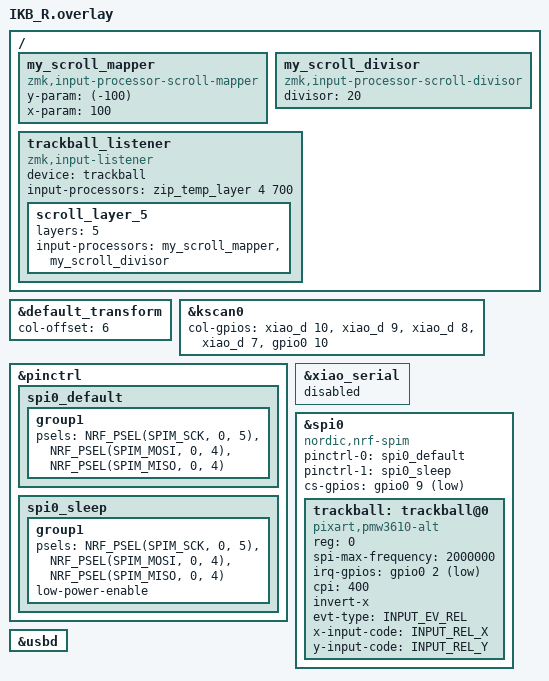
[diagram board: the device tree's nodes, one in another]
/* =========================================================
 * Date: 2026-04-12
 * Filename: config/boards/shields/Test/IKB_R.overlay
 * @details
 * スクロールの上下反転と、スクロール感度（細かさ）の調整を行いました。
 * ZMKの scroll_mapper の仕様に基づき、Y軸の入力乗数を負の値にして
 * 上下を反転させ、変換の分母（divisor）を調整してスクロールを細かくしています。
 * ========================================================= */

#include "IKB.dtsi"
#include <zephyr/dt-bindings/input/input-event-codes.h>
#include <dt-bindings/zmk/pointing.h>
#include <input/processors.dtsi>

&default_transform {
    col-offset = <6>;
};

&kscan0 {
    col-gpios
        = <&xiao_d 10 GPIO_ACTIVE_HIGH>
        , <&xiao_d 9 GPIO_ACTIVE_HIGH> 
        , <&xiao_d 8 GPIO_ACTIVE_HIGH> 
        , <&xiao_d 7 GPIO_ACTIVE_HIGH> 
        , <&gpio0 10 GPIO_ACTIVE_HIGH>
        ;
};

/ {
    /* ---------------------------------------------------
     * 【修正】スクロール変換のカスタム設定
     * 標準の zip_xy_to_scroll_mapper の挙動を上書きし、
     * Y軸の反転と感度（細かさ）の調整を行います。
     * --------------------------------------------------- */
    my_scroll_mapper: my_scroll_mapper {
        compatible = "zmk,input-processor-scroll-mapper";
        /* Y軸の移動量をスクロールに変換。値を変えずに方向だけ反転させるために -100 (マイナス100%) を指定 */
        y-param = <(-100)>;
        /* X軸（横スクロール）はそのまま 100% で変換 */
        x-param = <100>;
    };

    /* カスタム設定したマッパーを通すための追加設定（動きを細かくする分母）*/
    my_scroll_divisor: my_scroll_divisor {
        compatible = "zmk,input-processor-scroll-divisor";
        /* 【ここでスクロールの細かさを調整します】
         * 数字を大きくするとスクロールが細かく(遅く)なり、
         * 数字を小さくするとスクロールが粗く(速く)なります。
         * デフォルトは 10 程度です。今回は少し細かくするため 20 に設定しています。
         * もっと細かくしたい場合は 30 や 40 にしてみてください。
         */
        divisor = <20>;
    };

    trackball_listener {
        compatible = "zmk,input-listener";
        device = <&trackball>; 

        input-processors = <&zip_temp_layer 4 700>;

        scroll_layer_5 {
            layers = <5>;
            /* 上記で作成した「反転マッパー」と「細かくするデバイザ」を適用します */
            input-processors = <&my_scroll_mapper>, <&my_scroll_divisor>;
        };
    };
};

&pinctrl {
    spi0_default: spi0_default {
        group1 {
            psels = <NRF_PSEL(SPIM_SCK, 0, 5)>,
                <NRF_PSEL(SPIM_MOSI, 0, 4)>,
                <NRF_PSEL(SPIM_MISO, 0, 4)>;
        };
    };

    spi0_sleep: spi0_sleep {
        group1 {
            psels = <NRF_PSEL(SPIM_SCK, 0, 5)>,
                <NRF_PSEL(SPIM_MOSI, 0, 4)>,
                <NRF_PSEL(SPIM_MISO, 0, 4)>;
            low-power-enable;
        };                              
    };
};

&xiao_serial { status = "disabled"; };

&spi0 {
    status = "okay";
    compatible = "nordic,nrf-spim";
    pinctrl-0 = <&spi0_default>;
    pinctrl-1 = <&spi0_sleep>;
    pinctrl-names = "default", "sleep";
    cs-gpios = <&gpio0 9 GPIO_ACTIVE_LOW>;

    trackball: trackball@0 {
        status = "okay";
        compatible = "pixart,pmw3610-alt";
        reg = <0>;
        spi-max-frequency = <2000000>;
        irq-gpios = <&gpio0 2 (GPIO_ACTIVE_LOW | GPIO_PULL_UP)>;
        
        cpi = <400>;
        invert-x;
        /* invert-y はマウスカーソル用の設定なのでコメントアウトのまま */

        evt-type = <INPUT_EV_REL>;
        x-input-code = <INPUT_REL_X>;
        y-input-code = <INPUT_REL_Y>;
    };
};

&usbd {
    status = "okay";
};
